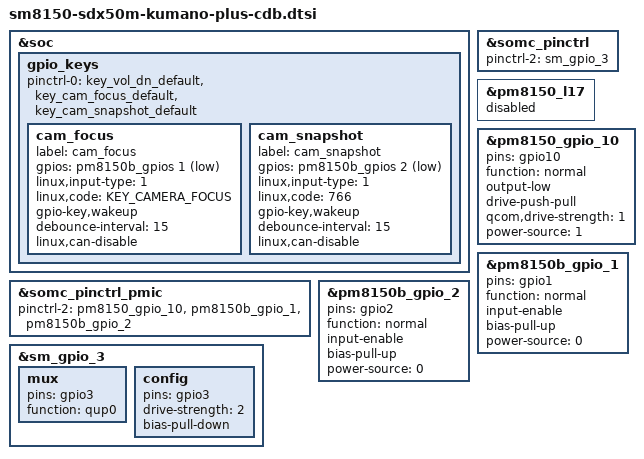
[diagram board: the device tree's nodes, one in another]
/* arch/arm64/boot/dts/somc/sm8150-sdx50m-kumano-plus-cdb.dtsi
 *
 * This program is free software; you can redistribute it and/or modify
 * it under the terms of the GNU General Public License version 2 and
 * only version 2 as published by the Free Software Foundation.
 *
 * This program is distributed in the hope that it will be useful,
 * but WITHOUT ANY WARRANTY; without even the implied warranty of
 * MERCHANTABILITY or FITNESS FOR A PARTICULAR PURPOSE.  See the
 * GNU General Public License for more details.
 */

#include "sm8150-sdx50m-kumano-plus-common.dtsi"

&soc {
	gpio_keys {
		pinctrl-0 = <&key_vol_dn_default
			     &key_cam_focus_default
			     &key_cam_snapshot_default>;

		cam_focus {
			label = "cam_focus";
			gpios = <&pm8150b_gpios 1 GPIO_ACTIVE_LOW>;
			linux,input-type = <1>;
			linux,code = <KEY_CAMERA_FOCUS>;
			gpio-key,wakeup;
			debounce-interval = <15>;
			linux,can-disable;
		};

		cam_snapshot {
			label = "cam_snapshot";
			gpios = <&pm8150b_gpios 2 GPIO_ACTIVE_LOW>;
			linux,input-type = <1>;
			linux,code = <766>;
			gpio-key,wakeup;
			debounce-interval = <15>;
			linux,can-disable;
		};
	};
};

&somc_pinctrl {
	/* If variant specific default setting is needed,
	fill pinctrl-2 value in <variant>.dtsi */
	pinctrl-2 = <&sm_gpio_3>;
};

&somc_pinctrl_pmic {
	/* If variant specific default setting is needed,
	fill pinctrl-2 value in <variant>.dtsi */
	pinctrl-2 = <&pm8150_gpio_10 &pm8150b_gpio_1 &pm8150b_gpio_2>;
};

/* Regulator config */
&pm8150_l17 {
	status = "disabled";
};

/* GPIO_10: VIB_LDO_EN */
&pm8150_gpio_10 {
	pins = "gpio10";
	function = "normal";
	/delete-property/ bias-high-impedance;
	output-low;
	drive-push-pull;
	qcom,drive-strength = <1>; /* Low */
	power-source = <1>;
};

/* GPIO_1: FOCUS_N */
&pm8150b_gpio_1 {
	pins = "gpio1";
	function = "normal";
	input-enable;
	bias-pull-up;
	power-source = <0>;
};

/* GPIO_2: SNAPSHOT_N */
&pm8150b_gpio_2 {
	pins = "gpio2";
	function = "normal";
	input-enable;
	bias-pull-up;
	power-source = <0>;
};

/* GPIO_3 : NFC_ESE_SPI_CS_N */
&sm_gpio_3 {
	mux {
		pins = "gpio3";
		function = "qup0";
	};

	config {
		pins = "gpio3";
		drive-strength = <2>;
		/delete-property/bias-disable;
		bias-pull-down;
		/delete-property/output-low;
	};
};

#include "synaptics-tcm-i2c.dtsi"
#include "somc-kumano-display.dtsi"
#include "somc-kumano-plus-display-cdb.dtsi"
#include "charger-kumano-common.dtsi"
#include "charger-kumano-plus-cdb.dtsi"
#include "somc-kumano-sensor_adux1050.dtsi"
